# MAX32600 register map
File version: 1.0
Registers are 32-bit, read-write, reset 0x0 unless marked. A register's access mark holds for its fields unless they carry their own. Offsets are from the block's base; [hi:lo] are bit positions; {n}, {i} and the like mark numbered series.

## CLKMAN — System Clock Manager
Base 0x40090400
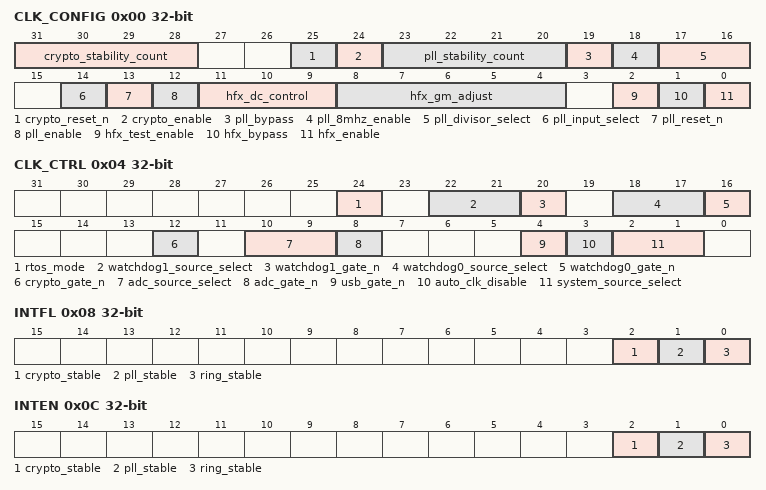
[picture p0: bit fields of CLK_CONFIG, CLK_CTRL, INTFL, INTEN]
0x00 CLK_CONFIG — System Clock Configuration
  [31:28] crypto_stability_count — Crypto Oscillator Stability Select
  [25] crypto_reset_n — Crypto Oscillator ResetN
  [24] crypto_enable — Crypto Oscillator Enable
  [23:20] pll_stability_count — PLL Stability Count Select
  [19] pll_bypass — Reserved Field; Do Not Modify
  [18] pll_8mhz_enable
  [17:16] pll_divisor_select
  [14] pll_input_select
  [13] pll_reset_n
  [12] pll_enable
  [11:9] hfx_dc_control
  [8:4] hfx_gm_adjust
  [2] hfx_test_enable — Reserved Field; Do Not Modify
  [1] hfx_bypass
  [0] hfx_enable
0x04 CLK_CTRL — System Clock Controls
  [24] rtos_mode
  [22:21] watchdog1_source_select — Watchdog 1 Clock Source Select
  [20] watchdog1_gate_n — Watchdog 1 Clock GateN
  [18:17] watchdog0_source_select — Watchdog 0 Clock Source Select
  [16] watchdog0_gate_n — Watchdog 0 Clock GateN
  [12] crypto_gate_n — Crypto Clock GateN
  [10:9] adc_source_select — ADC Clock Source Select
  [8] adc_gate_n — ADC Clock GateN
  [4] usb_gate_n — USB Clock GateN
  [3] auto_clk_disable — Auto Clock Disable
  [2:1] system_source_select — System Clock Source Select
0x08 INTFL — Interrupt Flags
  [2] crypto_stable write-1-clears — Crypto Oscillator Stable Int Flag
  [1] pll_stable write-1-clears — PLL Output Stable Int Flag
  [0] ring_stable write-1-clears — 24MHz Relaxation Osc Stable Int Flag
0x0C INTEN — Interrupt Enable/Disable Controls
  [2] crypto_stable — Crypto Oscillator Stable Int Enable
  [1] pll_stable — PLL Output Stable Int Enable
  [0] ring_stable — 24MHz Relaxation Oscillator Stable Int Enable
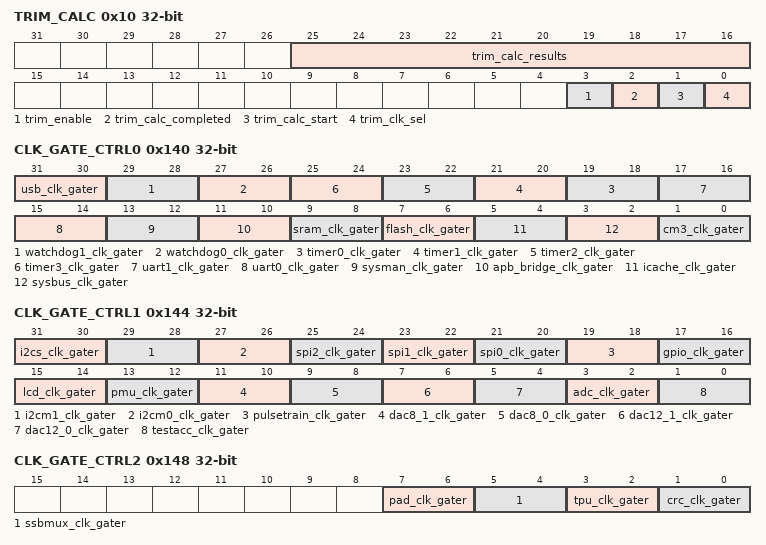
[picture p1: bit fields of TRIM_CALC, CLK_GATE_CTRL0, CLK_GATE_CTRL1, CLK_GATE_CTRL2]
0x10 TRIM_CALC — Trim Calculation Controls
  [25:16] trim_calc_results ro — Trim Calculation Results
  [3] trim_enable — Trim Logic Enable
  [2] trim_calc_completed ro — Trim Calculation Completed
  [1] trim_calc_start — Start Trim Calculation
  [0] trim_clk_sel — Trim Clock Select
0x24 I2C_TIMER_CTRL — I2C Timer Control
  [0] i2c_1ms_timer_en — I2C 1ms Timer Enable
0x40 CLK_CTRL_0_SYSTEM — Control Settings for CLK0 - System Clock
  [3:0] sys_clk_scale
0x44 CLK_CTRL_1_GPIO — Control Settings for CLK1 - GPIO Module Clock
  [3:0] gpio_clk_scale
0x48 CLK_CTRL_2_PT — Control Settings for CLK2 - Pulse Train Module Clock
  [3:0] pulse_train_clk_scale
{0x40+4i} CLK_CTRL_{i}_SPI{i-3} (i=3..5) — Control Settings for CLK{i} - SPI{i-3} Master Clock
  [3:0] spi{i-3}_clk_scale
0x58 CLK_CTRL_6_I2CM — Control Settings for CLK6 - Clock for all I2C Masters
  [3:0] i2cm_clk_scale
0x5C CLK_CTRL_7_I2CS — Control Settings for CLK7 - I2C Slave Clock
  [3:0] i2cs_clk_scale
0x60 CLK_CTRL_8_LCD_CHPUMP — Control Settings for CLK8 - LCD Charge Pump Clock
  [3:0] lcd_clk_scale
0x64 CLK_CTRL_9_PUF — Control Settings for CLK9 - PUF Clock
  [3:0] puf_clk_scale
0x68 CLK_CTRL_10_PRNG — Control Settings for CLK10 - PRNG Clock
  [3:0] prng_clk_scale
0x6C CLK_CTRL_11_WDT0 — Control Settings for CLK11 - Watchdog Timer 0 ScaledSysClk
  [3:0] watchdog0_clk_scale
0x70 CLK_CTRL_12_WDT1 — Control Settings for CLK12 - Watchdog Timer 1 ScaledSysClk
  [3:0] watchdog1_clk_scale
0x74 CLK_CTRL_13_RTC_INT_SYNC — Control Settings for CLK13 - RTC Interrupt Sync Clock
  [3:0] rtc_clk_scale
0x78 CLK_CTRL_14_DAC0 — Control Settings for CLK14 - 12-bit DAC 0 Clock
  [3:0] dac0_clk_scale
0x7C CLK_CTRL_15_DAC1 — Control Settings for CLK15 - 12-bit DAC 1 Clock
  [3:0] dac1_clk_scale
0x80 CLK_CTRL_16_DAC2 — Control Settings for CLK16 - 8-bit DAC 0 Clock
  [3:0] dac2_clk_scale
0x84 CLK_CTRL_17_DAC3 — Control Settings for CLK17 - 8-bit DAC 1 Clock
  [3:0] dac3_clk_scale
0x100 CRYPT_CLK_CTRL_0_AES — Control Settings for Crypto Clock 0 - AES
  [3:0] aes_clk_scale
0x104 CRYPT_CLK_CTRL_1_MAA — Control Settings for Crypto Clock 1 - MAA
  [3:0] umaa_clk_scale
0x108 CRYPT_CLK_CTRL_2_PRNG — Control Settings for Crypto Clock 2 - PRNG
  [3:0] prng_clk_scale
0x140 CLK_GATE_CTRL0 — Dynamic Clock Gating Control Register 0
  [31:30] usb_clk_gater — Clock Gating Control for USB
  [29:28] watchdog1_clk_gater — Clock Gating Control for WDT 1
  [27:26] watchdog0_clk_gater — Clock Gating Control for WDT 0
  [2n+19:2n+18] timer{n}_clk_gater (n=0..3) — Clock Gating Control for Timer Module {n}
  [17:16] uart1_clk_gater — Clock Gating Control for UART 1
  [15:14] uart0_clk_gater — Clock Gating Control for UART 0
  [13:12] sysman_clk_gater — Clock Gating Control for Clkman/Pwrman/IOman
  [11:10] apb_bridge_clk_gater — Clock Gating Control for AHB-to-APB Bridge
  [9:8] sram_clk_gater — Clock Gating Control for SRAM
  [7:6] flash_clk_gater — Clock Gating Control for Flash Memory
  [5:4] icache_clk_gater — Clock Gating Control for Instruction Cache
  [3:2] sysbus_clk_gater — Clock Gating Control for SysBus
  [1:0] cm3_clk_gater — Clock Gating Control for CM3 CPU
0x144 CLK_GATE_CTRL1 — Dynamic Clock Gating Control Register 1
  [31:30] i2cs_clk_gater — Clock Gating Control for I2C Slave
  [29:28] i2cm1_clk_gater — Clock Gating Control for I2C Master 1
  [27:26] i2cm0_clk_gater — Clock Gating Control for I2C Master 0
  [25:24] spi2_clk_gater — Clock Gating Control for SPI 2
  [23:22] spi1_clk_gater — Clock Gating Control for SPI 1
  [21:20] spi0_clk_gater — Clock Gating Control for SPI 0
  [19:18] pulsetrain_clk_gater — Clock Gating Control for Pulse Train Generators
  [17:16] gpio_clk_gater — Clock Gating Control for GPIO
  [15:14] lcd_clk_gater — Clock Gating Control for LCD
  [13:12] pmu_clk_gater — Clock Gating Control for DMA (PMU)
  [11:10] dac8_1_clk_gater — Clock Gating Control for DAC3
  [9:8] dac8_0_clk_gater — Clock Gating Control for DAC2
  [7:6] dac12_1_clk_gater — Clock Gating Control for DAC1
  [5:4] dac12_0_clk_gater — Clock Gating Control for DAC0
  [3:2] adc_clk_gater — Clock Gating Control for ADC
  [1:0] testacc_clk_gater — Clock Gating Control for TestAcc
0x148 CLK_GATE_CTRL2 — Dynamic Clock Gating Control Register 2
  [7:6] pad_clk_gater — Clock Gating Control for Pad Interface
  [5:4] ssbmux_clk_gater — Clock Gating Control for SSB Mux
  [3:2] tpu_clk_gater — Clock Gating Control for TPU
  [1:0] crc_clk_gater — Clock Gating Control for CRC16/32 Engine
